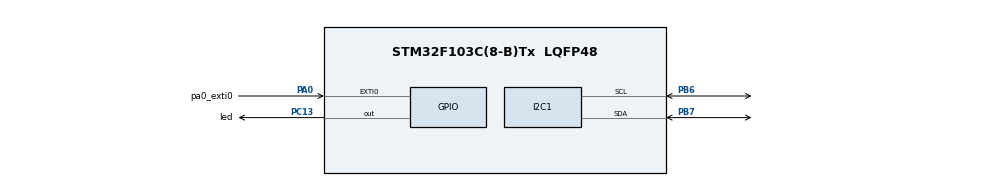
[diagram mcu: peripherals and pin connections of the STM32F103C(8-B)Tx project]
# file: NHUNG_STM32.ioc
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Mcu.Family=STM32F1
Mcu.Name=STM32F103C(8-B)Tx
Mcu.Package=LQFP48
NVIC.EXTI0_IRQn=true\:0\:0\:false\:false\:true\:true\:true\:true
NVIC.PriorityGroup=NVIC_PRIORITYGROUP_4
PA0-WKUP.GPIO_Label=pa0_exti0
PA0-WKUP.GPIO_ModeDefaultEXTI=GPIO_MODE_IT_FALLING
PA0-WKUP.GPIO_PuPd=GPIO_PULLUP
PA0-WKUP.Signal=GPXTI0
PA13.Mode=Serial_Wire
PA13.Signal=SYS_JTMS-SWDIO
PA14.Mode=Serial_Wire
PA14.Signal=SYS_JTCK-SWCLK
PB6.Mode=I2C
PB6.Signal=I2C1_SCL
PB7.Mode=I2C
PB7.Signal=I2C1_SDA
PC13-TAMPER-RTC.GPIO_Label=led
PC13-TAMPER-RTC.GPIO_PuPd=GPIO_PULLUP
PC13-TAMPER-RTC.Signal=GPIO_Output
ProjectManager.HeapSize=0x200
ProjectManager.StackSize=0x400
ProjectManager.TargetToolchain=STM32CubeIDE
RCC.APB1Freq_Value=8000000
RCC.APB2Freq_Value=8000000
board=custom

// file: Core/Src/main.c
#include "main.h"
#include<stdio.h>
#include"I2C_LCD.h"

I2C_HandleTypeDef hi2c1;

void SystemClock_Config(void);
static void MX_GPIO_Init(void);
static void MX_I2C1_Init(void);
/* USER CODE BEGIN PFP */
volatile uint32_t xung_cam_bien = 0;  // Biến đếm số xung
// Hàm xử lý ngắt khi có xung từ cảm biến
volatile uint8_t flag_led = 0; // led sangs khi co xung
//volatile double tong_luong_nuoc = 0.0;
void HAL_GPIO_EXTI_Callback(uint16_t GPIO_Pin)
{
    if (GPIO_Pin == pa0_exti0_Pin)  // Nếu tín hiệu đến từ PA0
    {
    	flag_led = 1;
    	HAL_GPIO_WritePin(led_GPIO_Port, led_Pin, 1);
        xung_cam_bien++;  // Tăng biến đếm mỗi khi nhận được xung

         }
}

int main(void)
{
  HAL_Init();

  /* Configure the system clock */
  SystemClock_Config();

  /* Initialize all configured peripherals */
  MX_GPIO_Init();
  MX_I2C1_Init();
  /* USER CODE BEGIN 2 */
  	LCD_Init();
  	LCD_SendString("LAP TRINH NHUNG");  // In dòng "Test LCD"
  	HAL_Delay(2000);  // Đợi
    LCD_Clear();
    char buffer[64];
  /* USER CODE END 2 */
    HAL_GPIO_WritePin(led_GPIO_Port, led_Pin, 1);
  /* Infinite loop */
  /* USER CODE BEGIN WHILE */
    while (1) {
        // Tính toán lưu lượng nước (L/phút)
        double luong_nuoc = 0.0;
        luong_nuoc = (double)xung_cam_bien / 7.5;  // Giả sử 1 xung = 7.5 L

        // Hiển thị số xung trên LCD
       // sprintf(buffer, "Count: %lu pulse", pulse_count);
        //LCD_PutCursor(0, 0);  // Di chuyển con trỏ đến dòng đầu tiên
        //LCD_SendString(buffer);

        // Hiển thị lưu lượng nước (L/phút)
        if (luong_nuoc > 0) {
            sprintf(buffer, " %.2f L/m ", luong_nuoc);
        } else {
            sprintf(buffer, "No_Data");
        }

        LCD_PutCursor(0, 0);  // Move cursor to the first line (row 0, col 0)
        LCD_SendString("Flow :");
        LCD_SendString(buffer);

        LCD_PutCursor(1, 0);  // Move cursor to the first line (row 0, col 0)

        LCD_SendString("Total :");
        sprintf(buffer," %.2f L ",luong_nuoc/60);
        LCD_SendString(buffer);

        // To display the current flow on the third line (row 2)
        if (flag_led) {
                HAL_GPIO_WritePin(led_GPIO_Port, led_Pin, GPIO_PIN_SET);
                flag_led = 0;  // Reset cờ để kiểm tra lại trong chu kỳ tiếp theo
            } else {
                HAL_GPIO_WritePin(led_GPIO_Port, led_Pin, GPIO_PIN_RESET);
            }

        // Đặt lại số xung cho chu kỳ đo lường tiếp theo
       // pulse_count = 0;

        HAL_Delay(500);  // Chờ 3 giây trước khi làm mới màn hình
    }
}
void SystemClock_Config(void)
{
  RCC_OscInitTypeDef RCC_OscInitStruct = {0};
  RCC_ClkInitTypeDef RCC_ClkInitStruct = {0};

  /** Initializes the RCC Oscillators according to the specified parameters
  * in the RCC_OscInitTypeDef structure.
  */
  RCC_OscInitStruct.OscillatorType = RCC_OSCILLATORTYPE_HSI;
  RCC_OscInitStruct.HSIState = RCC_HSI_ON;
  RCC_OscInitStruct.HSICalibrationValue = RCC_HSICALIBRATION_DEFAULT;
  RCC_OscInitStruct.PLL.PLLState = RCC_PLL_NONE;
  if (HAL_RCC_OscConfig(&RCC_OscInitStruct) != HAL_OK)
  {
    Error_Handler();
  }

  /** Initializes the CPU, AHB and APB buses clocks
  */
  RCC_ClkInitStruct.ClockType = RCC_CLOCKTYPE_HCLK|RCC_CLOCKTYPE_SYSCLK
                              |RCC_CLOCKTYPE_PCLK1|RCC_CLOCKTYPE_PCLK2;
  RCC_ClkInitStruct.SYSCLKSource = RCC_SYSCLKSOURCE_HSI;
  RCC_ClkInitStruct.AHBCLKDivider = RCC_SYSCLK_DIV1;
  RCC_ClkInitStruct.APB1CLKDivider = RCC_HCLK_DIV1;
  RCC_ClkInitStruct.APB2CLKDivider = RCC_HCLK_DIV1;

  if (HAL_RCC_ClockConfig(&RCC_ClkInitStruct, FLASH_LATENCY_0) != HAL_OK)
  {
    Error_Handler();
  }
}

static void MX_I2C1_Init(void)
{

  hi2c1.Instance = I2C1;
  hi2c1.Init.ClockSpeed = 100000;
  hi2c1.Init.DutyCycle = I2C_DUTYCYCLE_2;
  hi2c1.Init.OwnAddress1 = 0;
  hi2c1.Init.AddressingMode = I2C_ADDRESSINGMODE_7BIT;
  hi2c1.Init.DualAddressMode = I2C_DUALADDRESS_DISABLE;
  hi2c1.Init.OwnAddress2 = 0;
  hi2c1.Init.GeneralCallMode = I2C_GENERALCALL_DISABLE;
  hi2c1.Init.NoStretchMode = I2C_NOSTRETCH_DISABLE;
  if (HAL_I2C_Init(&hi2c1) != HAL_OK)
  {
    Error_Handler();
  }

}

static void MX_GPIO_Init(void)
{
  GPIO_InitTypeDef GPIO_InitStruct = {0};

  /* GPIO Ports Clock Enable */
  __HAL_RCC_GPIOC_CLK_ENABLE();
  __HAL_RCC_GPIOA_CLK_ENABLE();
  __HAL_RCC_GPIOB_CLK_ENABLE();

  /*Configure GPIO pin Output Level */
  HAL_GPIO_WritePin(led_GPIO_Port, led_Pin, GPIO_PIN_RESET);

  /*Configure GPIO pin : led_Pin */
  GPIO_InitStruct.Pin = led_Pin;
  GPIO_InitStruct.Mode = GPIO_MODE_OUTPUT_PP;
  GPIO_InitStruct.Pull = GPIO_PULLUP;
  GPIO_InitStruct.Speed = GPIO_SPEED_FREQ_LOW;
  HAL_GPIO_Init(led_GPIO_Port, &GPIO_InitStruct);

  /*Configure GPIO pin : pa0_exti0_Pin */
  GPIO_InitStruct.Pin = pa0_exti0_Pin;
  GPIO_InitStruct.Mode = GPIO_MODE_IT_FALLING;
  GPIO_InitStruct.Pull = GPIO_PULLUP;
  HAL_GPIO_Init(pa0_exti0_GPIO_Port, &GPIO_InitStruct);

  /* EXTI interrupt init*/
  HAL_NVIC_SetPriority(EXTI0_IRQn, 0, 0);
  HAL_NVIC_EnableIRQ(EXTI0_IRQn);

}

void Error_Handler(void)
{
  __disable_irq();
  while (1)
  {
  }
}
